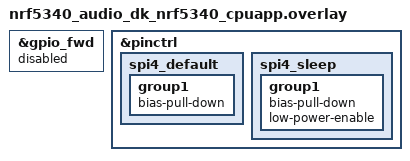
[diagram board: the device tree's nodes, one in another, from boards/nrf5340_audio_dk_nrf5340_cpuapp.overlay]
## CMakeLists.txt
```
#
# Copyright (c) 2026 Nordic Semiconductor ASA
#
# SPDX-License-Identifier: LicenseRef-Nordic-5-Clause
#

cmake_minimum_required(VERSION 3.20.0)

# Register zego bricks: button, led, wifi, network, wifi_ble_prov.
# Paths are relative to this CMakeLists.txt which lives inside zego/, so
# sibling bricks are under ../bricks/<name>/.
get_filename_component(ZEGO_BUTTON_DIR       ${CMAKE_CURRENT_SOURCE_DIR}/../bricks/button       REALPATH)
get_filename_component(ZEGO_LED_DIR          ${CMAKE_CURRENT_SOURCE_DIR}/../bricks/led          REALPATH)
get_filename_component(ZEGO_WIFI_DIR         ${CMAKE_CURRENT_SOURCE_DIR}/../bricks/wifi         REALPATH)
get_filename_component(ZEGO_NETWORK_DIR      ${CMAKE_CURRENT_SOURCE_DIR}/../bricks/network      REALPATH)
get_filename_component(ZEGO_WIFI_BLE_PROV_DIR ${CMAKE_CURRENT_SOURCE_DIR}/../bricks/wifi_ble_prov REALPATH)
get_filename_component(ZEGO_MEMONITOR_DIR    ${CMAKE_CURRENT_SOURCE_DIR}/../bricks/memonitor    REALPATH)
get_filename_component(ZEGO_UX_DIR            ${CMAKE_CURRENT_SOURCE_DIR}/../bricks/ux           REALPATH)
get_filename_component(ZEGO_NTP_DIR           ${CMAKE_CURRENT_SOURCE_DIR}/../bricks/ntp          REALPATH)
list(APPEND EXTRA_ZEPHYR_MODULES
  ${ZEGO_BUTTON_DIR}
  ${ZEGO_LED_DIR}
  ${ZEGO_WIFI_DIR}
  ${ZEGO_NETWORK_DIR}
  ${ZEGO_WIFI_BLE_PROV_DIR}
  ${ZEGO_MEMONITOR_DIR}
  ${ZEGO_UX_DIR}
  ${ZEGO_NTP_DIR}
)

find_package(Zephyr REQUIRED HINTS $ENV{ZEPHYR_BASE})
project(nordic_wifi_app_template)

target_include_directories(app PUBLIC ${ZEPHYR_BASE}/subsys/net/ip)

# All bricks are provided via EXTRA_ZEPHYR_MODULES above (zego/wifi,
# zego/network, zego/button, zego/led, zego/wifi_ble_prov, zego/ux).
# Add application modules below as the project grows.

# APP_VERSION_STRING, PRD_VERSION, SPECS_VERSION are injected by
# zego/wifi/CMakeLists.txt via target_compile_definitions.
target_sources(app PRIVATE
  src/main.c
  src/modules/network/net_event_mgmt_app.c
)
```

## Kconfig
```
#
# Copyright (c) 2026 Nordic Semiconductor ASA
#
# SPDX-License-Identifier: LicenseRef-Nordic-5-Clause
#

menu "Nordic Wi-Fi App Template"

config APP_WIFI_SSID
	string "Wi-Fi SoftAP SSID"
	default "nRF7x_AP"
	help
	  SSID used when operating in SoftAP or P2P_GO mode.

config APP_WIFI_PASSWORD
	string "Wi-Fi SoftAP Password"
	default "12345678"
	help
	  Password for SoftAP (min 8 characters for WPA2).

# mode_selector and network Kconfig provided by zego/wifi and zego/network
# (EXTRA_ZEPHYR_MODULES) — no rsource needed here.
# button, led, and ux Kconfig registered via EXTRA_ZEPHYR_MODULES
# (zego/button, zego/led, zego/ux).

endmenu

source "Kconfig.zephyr"
```

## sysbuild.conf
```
#
# Copyright (c) 2026 Nordic Semiconductor ASA
#
# SPDX-License-Identifier: LicenseRef-Nordic-5-Clause
#

# Wi-Fi support
SB_CONFIG_WIFI_NRF70=y
# Partition Manager deprecated after NCS v3.3.0
SB_CONFIG_PARTITION_MANAGER=n
SB_CONFIG_MERGED_HEX_FILES=y

# nRF5340 (nrf7002dk) only: BLE controller runs on the network core over IPC.
# Build the upstream Zephyr hci_ipc sample as the netcore image so
# CONFIG_ZEGO_WIFI_BLE_PROV can open the HCI driver.
# On nrf54lm20dk SUPPORT_NETCORE=n (single-core SoC), so this has no effect.
SB_CONFIG_NETCORE_HCI_IPC=y
```

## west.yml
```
manifest:
  version: "0.13"

  defaults:
    remote: ncs

  remotes:
    - name: ncs
      url-base: https://github.com/nrfconnect

  projects:
    # NCS imports zephyr, bootloader, modules, nrfxlib, tools, etc.
    - name: sdk-nrf
      path: nrf
      revision: v3.3.0
      import: true
      remote: ncs
```

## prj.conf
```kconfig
#
# Copyright (c) 2026 Nordic Semiconductor ASA
#
# SPDX-License-Identifier: LicenseRef-Nordic-5-Clause
#

# =========================================================================
# Configuration coverage priority:
# Command line > Overlay files > project boards/<board>.conf > prj.conf > Board defconfig
# (highest)                                                              (lowest)
# =========================================================================

# =========================================================================
# This file contains only:
#   - System-level configuration that belongs to no single module
#   - Module enable/disable flags
#   - Log-level choices (cannot be set via Kconfig.defaults)
#   - Project-specific overrides that differ from module defaults
#   - Shared cross-module settings (TLS, mbedTLS)
#   - Hardware-specific memory and stack tuning
# Module-specific defaults live in each module's Kconfig.defaults file.
# =========================================================================

# =========================================================================
# prj.conf should contain the following sections, if needed, in this order,
# with the given headings. Config values that already match the Kconfig
# default (or are already selected transitively) should be commented out.
# Top-level section headings use "=" bars; sub-sections within a section
# use "-" bars:
# =========================================================================
# Document versions — keep in sync with docs/pm-prd/PRD.md and docs/dev-specs/overview.md Changelog timestamps
# General System Configuration - General system configuration
# ZEGO Module: button/led/wifi/network - configurations for different Zego modules
# APP  Module: app/ntp/app_http/app_mqtt - configurations for different APP modules
# Thread Stack Configuration - Thread stack configuration
# Heap Configuration - Heap configuration   
# mbedTLS - mbedTLS configuration
# Shell - shell configuration
# Logging Configuration
# Optimization - Optimization configuration
# =========================================================================
# Reminder: this header block (down to this line) should be copied verbatim
# into any new prj.conf-style config file (e.g. new boards/*.conf files) so
# the same section order and bar conventions are followed consistently.
# =========================================================================

# =========================================================================
# Document versions — keep in sync with docs/pm-prd/PRD.md and
# docs/dev-specs/overview.md Changelog timestamps.
# =========================================================================
CONFIG_ZEGO_APP_PRD_VERSION="2026-07-01-10-50"
CONFIG_ZEGO_APP_SPECS_VERSION="2026-07-01-10-54"

# =========================================================================
# General System Configuration - General system configuration
# =========================================================================

# -------------------------------------------------------------------------
# System
# -------------------------------------------------------------------------
# CONFIG_REBOOT already unconditionally selected by ZEGO_WIFI_MODE_SELECTOR
# (zego/wifi's Kconfig, auto-enabled here via NRF70_AP_MODE) — verified via
# build (.config unchanged).
# CONFIG_REBOOT=y

# -------------------------------------------------------------------------
# Debugging
# -------------------------------------------------------------------------
# CONFIG_STACK_SENTINEL=y
CONFIG_DEBUG_COREDUMP=y
CONFIG_DEBUG_COREDUMP_BACKEND_LOGGING=y
CONFIG_DEBUG_COREDUMP_MEMORY_DUMP_MIN=y
CONFIG_SHELL_CMDS_RESIZE=n

# -------------------------------------------------------------------------
# Kernel options
# -------------------------------------------------------------------------
CONFIG_ENTROPY_GENERATOR=y
# CONFIG_INIT_STACKS already selected below by CONFIG_ZEGO_MEMONITOR_ZVIEW —
# verified via build (.config unchanged).
# CONFIG_INIT_STACKS=y

# -------------------------------------------------------------------------
# Eventfd — WPA supplicant needs more than 2
# -------------------------------------------------------------------------
CONFIG_EVENTFD=y
CONFIG_ZVFS_OPEN_MAX=48
CONFIG_ZVFS_EVENTFD_MAX=16
CONFIG_POSIX_API=y

# -------------------------------------------------------------------------
# SMF + Zbus
# -------------------------------------------------------------------------
# SMF and ZBUS already selected by zego/button and zego/led ("select SMF" /
# "select ZBUS" in their Kconfig) — verified via build (.config unchanged).
# CONFIG_SMF=y
CONFIG_SMF_INITIAL_TRANSITION=y
CONFIG_SMF_ANCESTOR_SUPPORT=y
# CONFIG_ZBUS=y
CONFIG_ZBUS_PRIORITY_BOOST=y
CONFIG_ZBUS_RUNTIME_OBSERVERS=y
CONFIG_ZBUS_MSG_SUBSCRIBER=y

# -------------------------------------------------------------------------
# GPIO / DK Library
# -------------------------------------------------------------------------
# GPIO and DK_LIBRARY already selected via ZEGO_BUTTON_BACKEND_DK /
# ZEGO_LED_BACKEND_DK (the default backend, confirmed in every boards/*.conf)
# -> DK_LIBRARY "select GPIO" — verified via build (.config unchanged).
# CONFIG_GPIO=y
# CONFIG_DK_LIBRARY=y

# -------------------------------------------------------------------------
# JSON
# -------------------------------------------------------------------------
CONFIG_JSON_LIBRARY=y

# -------------------------------------------------------------------------
# Persistent storage — NVS / Settings / Flash
# -------------------------------------------------------------------------
# Used by the Wi-Fi mode selector (persists the active STA/SoftAP/P2P_GO
# mode across reboots) and by the Wi-Fi credentials backend
# (CONFIG_WIFI_CREDENTIALS_BACKEND_SETTINGS, persists STA credentials).
# SETTINGS / FLASH / FLASH_MAP / FLASH_PAGE_LAYOUT already unconditionally
# selected by ZEGO_WIFI_MODE_SELECTOR (zego/wifi's Kconfig, auto-enabled here
# via NRF70_AP_MODE) — verified via build (.config unchanged).
# CONFIG_SETTINGS=y
CONFIG_SETTINGS_NVS=y
CONFIG_NVS=y
# CONFIG_FLASH=y
# CONFIG_FLASH_MAP=y
# CONFIG_FLASH_PAGE_LAYOUT=y

# =========================================================================
# ZEGO Module: button/led/wifi/network - configurations for different Zego modules
# =========================================================================

# -------------------------------------------------------------------------
# Zego module configuration
# -------------------------------------------------------------------------
CONFIG_ZEGO_BUTTON=y
CONFIG_ZEGO_LED=y

CONFIG_ZEGO_WIFI=y
# Default mode: STA — change to SOFTAP or P2P_GO via the mode-selector shell
CONFIG_ZEGO_WIFI_DEFAULT_MODE_STA=y
# Enable all four Wi-Fi modes on all boards.
CONFIG_ZEGO_WIFI_MODE_SOFTAP_ENABLED=y
CONFIG_ZEGO_WIFI_LOG_LEVEL_INF=y

CONFIG_ZEGO_WIIF_SOFTAP_SSID="nRF7x_AP"
CONFIG_ZEGO_WIIF_SOFTAP_PASSWORD="12345678"

# BLE Wi-Fi provisioning (zego/wifi_ble_prov module)
# Disabled per-board when flash budget is too tight (see boards/*.conf).
# Log levels only set in boards conf where the module is actually enabled,
# to avoid Kconfig "choice symbol selected but no selection" warnings.
# CONFIG_ZEGO_WIFI_BLE_PROV=y

# P2P_GC has no target-GO-MAC build option: the GO is paired at runtime via a
# Button 0 double-click (WPS PIN) and the learned MAC is stored in NVS.

# -------------------------------------------------------------------------
# Wi-Fi Configuration (STA + SoftAP + P2P)
# -------------------------------------------------------------------------
# WIFI / WIFI_NRF70 / WIFI_NM_WPA_SUPPLICANT: now unconditionally selected by
# ZEGO_NETWORK (zego/network's Kconfig) now that the ZEGO_NETWORK/ZEGO_WIFI/
# NETWORKING Kconfig cycle is fixed — verified via build (.config unchanged).
# CONFIG_WIFI=y
# CONFIG_WIFI_NRF70=y

# WPA supplicant — supports STA and SoftAP; add wifi-p2p snippet for P2P + WPS
# CONFIG_WIFI_NM_WPA_SUPPLICANT=y
CONFIG_WIFI_NM_WPA_SUPPLICANT_AP=y

# WEP and WPA1/TKIP (LEGACY_CRYPTO) are both cryptographically broken (WEP:
# full key recovery in minutes via aircrack-ng-class attacks; TKIP: Beck-Tews/
# Ohigashi-Morii partial plaintext recovery) and have been out of Wi-Fi
# Alliance certification since 2004 / 2012 respectively. WPA2-AES/CCMP has
# been mandatory in every certified AP since 2006, so a router with no WPA2
# fallback is effectively extinct — the compatibility cost of dropping both
# is negligible, and doing so removes an RC4/MD5 downgrade attack surface
# from this device's Wi-Fi stack entirely. This app only uses personal
# WPA2/WPA3-PSK (no enterprise/EAP), which doesn't touch either symbol.
CONFIG_WIFI_NM_WPA_SUPPLICANT_WEP=n
CONFIG_WIFI_NM_WPA_SUPPLICANT_LEGACY_CRYPTO=n

# nRF70 SoftAP mode
CONFIG_NRF70_AP_MODE=y
CONFIG_NRF_WIFI_LOW_POWER=n
# Limit SoftAP to 3 simultaneous clients (Zephyr default is 4)
CONFIG_WIFI_MGMT_AP_MAX_NUM_STA=3

# nRF70 P2P mode (Wi-Fi Direct) — not enabled here; add the wifi-p2p snippet
# (-Dnordic-wifi-app-template_SNIPPET=wifi-p2p) to enable it. The snippet sets
# CONFIG_NRF70_P2P_MODE=y, which in turn enables P2P_GO and P2P_GC as
# selectable Wi-Fi modes by default (ZEGO_WIFI_MODE_P2P_GO_ENABLED /
# _GC_ENABLED both default y when NRF70_P2P_MODE=y — see zego/bricks/wifi/Kconfig).

# -------------------------------------------------------------------------
# Networking
# -------------------------------------------------------------------------
# CONFIG_NETWORKING already unconditionally selected by ZEGO_WIFI (zego/wifi's
# Kconfig) — verified via build (.config unchanged).
# CONFIG_NETWORKING=y
# CONFIG_NET_SOCKETS / NET_IPV4 / NET_UDP / NET_TCP / NET_DHCPV4 already
# unconditionally selected by ZEGO_NETWORK (zego/network's Kconfig) —
# verified via build (.config unchanged).
# CONFIG_NET_SOCKETS=y
# CONFIG_NET_IPV4=y
# CONFIG_NET_UDP=y
# CONFIG_NET_TCP=y
CONFIG_NET_IPV6=n

# DHCP Server (SoftAP / P2P_GO)
# CONFIG_NET_DHCPV4=y
CONFIG_NET_DHCPV4_SERVER=y
CONFIG_NET_DHCPV4_SERVER_ADDR_COUNT=3
# Static IP for SoftAP / P2P_GO
CONFIG_NET_CONFIG_SETTINGS=y
CONFIG_NET_CONFIG_MY_IPV4_ADDR="192.168.7.1"
CONFIG_NET_CONFIG_MY_IPV4_NETMASK="255.255.255.0"
CONFIG_NET_CONFIG_MY_IPV4_GW="192.168.7.1"
CONFIG_NET_CONFIG_INIT_TIMEOUT=0

# -------------------------------------------------------------------------
# STA mode — Connection Manager + Wi-Fi Credentials
# -------------------------------------------------------------------------
# CONFIG_NET_CONNECTION_MANAGER / L2_WIFI_CONNECTIVITY / WIFI_CREDENTIALS /
# DNS_RESOLVER already unconditionally selected by ZEGO_NETWORK (zego/network's
# Kconfig) — verified via build (.config unchanged).
# CONFIG_NET_CONNECTION_MANAGER=y
# CONFIG_L2_WIFI_CONNECTIVITY=y
CONFIG_L2_WIFI_CONNECTIVITY_AUTO_CONNECT=n
CONFIG_L2_WIFI_CONNECTIVITY_AUTO_DOWN=n

# Persistent credential store — enables 'wifi cred' shell commands
# CONFIG_WIFI_CREDENTIALS=y
CONFIG_WIFI_CREDENTIALS_BACKEND_SETTINGS=y
# CONFIG_DNS_RESOLVER=y
CONFIG_DNS_RESOLVER_AUTO_INIT=y

# -------------------------------------------------------------------------
# Network buffers — tuned for reliable operation
# -------------------------------------------------------------------------
# Using default VAR pool (NET_BUF_POOL_VAR_DEFINE / k_heap).
# Each buffer is sized to the actual payload, so small packets (DNS, ACKs)
# don't waste a full MTU slot. The pool heap is a dedicated static arena
# (not drawn from _system_heap) visible to ZView as net_buf_mem_pool_rx/tx_bufs.
CONFIG_NET_PKT_RX_COUNT=16
CONFIG_NET_PKT_TX_COUNT=24
CONFIG_NET_BUF_RX_COUNT=16
CONFIG_NET_BUF_TX_COUNT=32
CONFIG_NRF70_RX_NUM_BUFS=16
CONFIG_NET_TC_TX_COUNT=1
CONFIG_NET_IF_UNICAST_IPV4_ADDR_COUNT=1
CONFIG_NET_MAX_CONTEXTS=16
CONFIG_NET_MAX_CONN=16
CONFIG_NET_CONTEXT_SYNC_RECV=y
CONFIG_NET_CONTEXT_RCVTIMEO=y
CONFIG_NET_L2_ETHERNET=y
CONFIG_NET_SOCKETS_POLL_MAX=10

# -------------------------------------------------------------------------
# P2P debug — enable wpa_supplicant MSG_DEBUG to see join_scan_count,
# "Failed to find BSS/GO", "Join scan attempt N", P2P state transitions.
# Very verbose: filter with 'grep P2P' in the terminal.
# Remove when debugging is done.
# -------------------------------------------------------------------------
#CONFIG_WIFI_NM_WPA_SUPPLICANT_LOG_LEVEL_DBG=y

CONFIG_ZEGO_NETWORK=y
CONFIG_ZEGO_NETWORK_LOG_LEVEL_INF=y

# -------------------------------------------------------------------------
# mDNS — device reachable as nrf7x.local on any active Wi-Fi interface
# -------------------------------------------------------------------------
#CONFIG_ZEGO_NETWORK_MDNS=y
#CONFIG_NET_HOSTNAME="nrf7x"
# Uncomment to also register _http._tcp.local DNS-SD service:
#CONFIG_ZEGO_NETWORK_MDNS_HTTP_PORT=80

# =========================================================================
# APP  Module: app/ntp/app_http/app_mqtt - configurations for different APP modules
# =========================================================================

# -------------------------------------------------------------------------
# UX module — Button 0 gestures + LED 0 Wi-Fi state feedback
# -------------------------------------------------------------------------
CONFIG_ZEGO_UX=y

# -------------------------------------------------------------------------
# memonitor — periodic heap + thread sampler, /api/heaps, /api/threads (FR-107/108)
# Set =n to disable: the Thread Monitor and Heap Monitor sections will be
# hidden automatically on the webpage.
# -------------------------------------------------------------------------
CONFIG_ZEGO_MEMONITOR=y
CONFIG_ZEGO_MEMONITOR_INTERVAL_MS=5000
# ZEGO_MEMONITOR_ZVIEW selects all required Kconfig symbols:
#   INIT_STACKS, THREAD_MONITOR, THREAD_STACK_INFO, THREAD_NAME,
#   THREAD_RUNTIME_STATS, SYS_HEAP_RUNTIME_STATS.
# CONFIG_STACK_SENTINEL=n is mandatory: it overwrites the 0xaa init-fill with
# 0xf0f0f0f0, causing ZView to report 100% stack usage on every thread.
CONFIG_ZEGO_MEMONITOR_ZVIEW=y
CONFIG_STACK_SENTINEL=n

# -------------------------------------------------------------------------
# ntp — SNTP time synchronization (zego/bricks/ntp)
# Uses pool.ntp.org by default (see zego/bricks/ntp/Kconfig for all options).
# -------------------------------------------------------------------------
CONFIG_ZEGO_NTP=y
CONFIG_ZEGO_NTP_LOG_LEVEL_INF=y
# Real-world timestamps in log output (requires ZEGO_NTP to set CLOCK_REALTIME)
CONFIG_LOG_TIMESTAMP_USE_REALTIME=y

# =========================================================================
# Thread Stack Configuration - Thread stack configuration
# =========================================================================
# All values measured on nRF54LM20DK + nRF7002EB2 using CONFIG_THREAD_ANALYZER.
# Sizing rule: max_hwm / 0.9 (10 % headroom). Adjust for your application load.
# Watermark Bytes 1496/0.9=1662 (WiFi reconnect + active uploads)
CONFIG_MAIN_STACK_SIZE=4096
# Watermark Bytes 4952/0.9=5502 (wpa_cli_cmd + _wpa_ctrl_command + zvfs_poll_internal)
CONFIG_SYSTEM_WORKQUEUE_STACK_SIZE=5502
# Watermark Bytes 4432/0.9=4924
CONFIG_NET_CONNECTION_MANAGER_MONITOR_STACK_SIZE=4924
# Watermark Bytes 1168/0.9=1297; kept at 2048 for network burst headroom
CONFIG_NET_RX_STACK_SIZE=2048
# Watermark Bytes 792/0.9=880; kept at 2048 for network burst headroom
CONFIG_NET_TX_STACK_SIZE=2048
# Watermark Bytes 2940/0.9=3266
CONFIG_NET_MGMT_EVENT_STACK_SIZE=3266
# Watermark Bytes 5392/0.9=5991 (measured on nRF54LM20DK + nRF7002EB2)
CONFIG_WIFI_NM_WPA_SUPPLICANT_THREAD_STACK_SIZE=8192
# Watermark Bytes 3896/0.9=4328
CONFIG_WIFI_NM_WPA_SUPPLICANT_WQ_STACK_SIZE=4328
# Watermark Bytes 1088/0.9=1208
CONFIG_NRF70_BH_WQ_STACK_SIZE=1208
# Watermark Bytes 792/0.9=880
CONFIG_NRF70_IRQ_WQ_STACK_SIZE=880
# Watermark Bytes 248/0.9=276
CONFIG_L2_WIFI_CONN_WQ_STACK_SIZE=2760

CONFIG_SHELL_STACK_SIZE=8192

# =========================================================================
# Heap Configuration - Heap configuration
# =========================================================================
# CONFIG_HEAP_MEM_POOL_SIZE is the user floor. Kconfig enforces a minimum equal
# to the sum of all HEAP_MEM_POOL_ADD_SIZE_* values (~184 KB for Wi-Fi + BLE):
#   ADD_SIZE_NRF70=150000  ADD_SIZE_HOSTAP=30000  ADD_SIZE_BOARD=4096  ADD_SIZE_POSIX=256
# Setting a value below that sum is silently raised to the sum unless
# HEAP_MEM_POOL_IGNORE_MIN=y is set.
# Runtime measurements: _system_heap peaked at 57928 B (89 %) of the previous
# 64780 B ceiling in STA/SoftAP mode. P2P_GO adds ~6-8 KB more for struct
# p2p_data, the P2P GO's wpa_auth context, and the PMKSA cache (528 B).
# Without enough headroom, pmksa_cache_auth_init() returns NULL, causing
# "PMKSA cache initialization failed" + "WPA initialization failed" and a
# 15 s WPS_CHECK_PIN ctrl-iface timeout.
# New ceiling: 131072 B (20 % headroom above estimated P2P_GO peak of ~104 KB).
# With NRF_WIFI_GLOBAL_HEAP=n and WIFI_NM_WPA_SUPPLICANT_GLOBAL_HEAP=n the
# HEAP_MEM_POOL_ADD_SIZE_* contributions from WiFi + WPA supplicant are removed.
# Only app-level allocations remain in _system_heap — re-measure after split.
CONFIG_HEAP_MEM_POOL_SIZE=4096
CONFIG_HEAP_MEM_POOL_IGNORE_MIN=y
# WiFi driver moved to dedicated K_HEAPs — visible as wifi_drv_ctrl_mem_pool and
# wifi_drv_data_mem_pool in ZView.
# Re-measure ZView watermarks after a full STA/P2P connect + TLS cycle, then set
# each to watermark / 0.8.
CONFIG_NRF_WIFI_GLOBAL_HEAP=n
CONFIG_NRF_WIFI_CTRL_HEAP_SIZE=16384
CONFIG_NRF_WIFI_DATA_HEAP_SIZE=40960
# WPA supplicant moved to dedicated K_HEAP — visible as wifi_nm_wpa_supplicant_mem_pool in ZView.
# Re-measure ZView watermark after a full connect cycle, then set to peak / 0.8.
# Use the shared Zephyr system heap for wpa_supplicant (the NCS default, =y).
# A dedicated supplicant K_HEAP (=n) was previously used for per-pool ZView
# monitoring, but it starved the P2P_GO hostapd WPS Registrar: wps_registrar_init()
# failed ("Failed to initialize WPS Registrar") and the GO AP interface never
# reached AP-ENABLED, so P2P pairing was impossible. The nRF P2P sample uses the
# global heap and works; matching it fixes the GO. Confirmed on hardware.
# (Trade-off: the supplicant heap no longer appears as a separate ZView pool;
# track it via the system-heap watermark instead.)
CONFIG_WIFI_NM_WPA_SUPPLICANT_GLOBAL_HEAP=y

# =========================================================================
# mbedTLS - mbedTLS configuration
# =========================================================================
CONFIG_MBEDTLS_ENABLE_HEAP=y
# Watermark Bytes 69504/0.8=86880 (measured with global heap; re-measure with dedicated heap)
CONFIG_MBEDTLS_HEAP_SIZE=86880
# NCS v3.4.0 updated Mbed TLS to v4.1.0, which removed the legacy mbedcrypto
# APIs and the "legacy crypto config path" this app previously routed through.
# CONFIG_NRF_SECURITY is now a computed symbol (auto-enabled for Nordic SoCs)
# and CONFIG_MBEDTLS_LEGACY_CRYPTO_C no longer exists, so neither is set here.
# Unlike a first assessment suggested, this is NOT a no-op change: nrf_security's
# PSA-only config generation did not forward MBEDTLS_MEMORY_DEBUG into the
# generated psa/crypto_config.h, so mbedtls_memory_buffer_alloc_cur_get()/
# _max_get() were unavailable and the mbedtls_heap row was omitted from ZView.
# Fixed by a vendored patch carried in zego/patches/nrf_security/ (reapply
# after west update) - see bricks/memonitor/Kconfig for the resulting
# CONFIG_MBEDTLS_MEMORY_DEBUG auto-select logic.

# =========================================================================
# Shell - shell configuration
# =========================================================================
# Shell — required for mode selector UX and wifi connect / wifi cred commands
CONFIG_SHELL=y
CONFIG_NET_L2_WIFI_SHELL=y
CONFIG_WIFI_SHELL_MAX_AP_STA=3

# =========================================================================
# Logging Configuration
# =========================================================================
CONFIG_LOG=y
CONFIG_LOG_BUFFER_SIZE=4096
# Deferred mode: log messages are queued and processed in the logging thread,
# not inline in the calling thread (net_mgmt event thread, etc.)
CONFIG_LOG_MODE_DEFERRED=y
# NET_LOG=y is required for any NET_*_LOG_LEVEL_* choice to become visible
# (all net module log choices depend on NET_LOG).
# All modules explicitly silenced to avoid FLASH overflow; only NET_SOCKETS at DBG.
CONFIG_NET_LOG=n
# CONFIG_NET_SOCKETS_LOG_LEVEL_INF=y
# # CONFIG_MQTT_LOG_LEVEL_DBG=y
# # CONFIG_MQTT_HELPER_LOG_LEVEL_DBG=y
# CONFIG_SOCKS_LOG_LEVEL_OFF=y
# CONFIG_TLS_CREDENTIALS_LOG_LEVEL_OFF=y
# CONFIG_DNS_RESOLVER_LOG_LEVEL_OFF=y
# CONFIG_DNS_SD_LOG_LEVEL_OFF=y
# CONFIG_DNS_SOCKET_DISPATCHER_LOG_LEVEL_OFF=y
# CONFIG_LATMON_LOG_LEVEL_OFF=y
# CONFIG_LLMNR_RESPONDER_LOG_LEVEL_OFF=y
# CONFIG_LWM2M_LOG_LEVEL_OFF=y
# CONFIG_MDNS_RESPONDER_LOG_LEVEL_OFF=y
# CONFIG_NET_6LO_LOG_LEVEL_OFF=y
# CONFIG_NET_ARP_LOG_LEVEL_OFF=y
# CONFIG_NET_CAPTURE_LOG_LEVEL_OFF=y
# CONFIG_NET_CONFIG_LOG_LEVEL_OFF=y
# CONFIG_NET_CONN_LOG_LEVEL_OFF=y
# CONFIG_NET_CONNECTION_MANAGER_LOG_LEVEL_OFF=y
# CONFIG_NET_CONTEXT_LOG_LEVEL_OFF=y
# CONFIG_NET_CORE_LOG_LEVEL_OFF=y
# CONFIG_NET_DHCPV4_LOG_LEVEL_OFF=y
# CONFIG_NET_DHCPV4_SERVER_LOG_LEVEL_OFF=y
# CONFIG_NET_DHCPV6_LOG_LEVEL_OFF=y
# CONFIG_NET_DSA_LOG_LEVEL_OFF=y
# CONFIG_NET_ETHERNET_BRIDGE_LOG_LEVEL_OFF=y
# CONFIG_NET_GPTP_LOG_LEVEL_OFF=y
# CONFIG_NET_HTTP_SERVER_LOG_LEVEL_OFF=y
# CONFIG_NET_ICMPV4_LOG_LEVEL_OFF=y
# CONFIG_NET_ICMPV6_LOG_LEVEL_OFF=y
# CONFIG_NET_IF_LOG_LEVEL_OFF=y
# CONFIG_NET_IPV4_LOG_LEVEL_OFF=y
# CONFIG_NET_IPV4_ACD_LOG_LEVEL_OFF=y
# CONFIG_NET_IPV4_AUTO_LOG_LEVEL_OFF=y
# CONFIG_NET_IPV6_LOG_LEVEL_OFF=y
# CONFIG_NET_IPV6_NBR_CACHE_LOG_LEVEL_OFF=y
# CONFIG_NET_IPV6_ND_LOG_LEVEL_OFF=y
# CONFIG_NET_IPV6_PE_LOG_LEVEL_OFF=y
# CONFIG_NET_L2_ETHERNET_LOG_LEVEL_OFF=y
# CONFIG_NET_L2_IEEE802154_LOG_LEVEL_OFF=y
# CONFIG_NET_L2_IPIP_LOG_LEVEL_OFF=y
# CONFIG_NET_L2_PPP_LOG_LEVEL_OFF=y
# CONFIG_NET_L2_VIRTUAL_LOG_LEVEL_OFF=y
# CONFIG_NET_L2_WIFI_MGMT_LOG_LEVEL_OFF=y
# CONFIG_NET_LLDP_LOG_LEVEL_OFF=y
# CONFIG_NET_MGMT_EVENT_LOG_LEVEL_OFF=y
# CONFIG_NET_OFFLOAD_LOG_LEVEL_OFF=y
# CONFIG_NET_PKT_FILTER_LOG_LEVEL_OFF=y
# CONFIG_NET_PMTU_LOG_LEVEL_OFF=y
# CONFIG_NET_PROMISC_LOG_LEVEL_OFF=y
# CONFIG_NET_PSEUDO_IFACE_LOG_LEVEL_OFF=y
# CONFIG_NET_ROUTE_LOG_LEVEL_OFF=y
# CONFIG_NET_STATISTICS_LOG_LEVEL_OFF=y
# CONFIG_NET_TC_LOG_LEVEL_OFF=y
# CONFIG_NET_TCP_LOG_LEVEL_OFF=y
# CONFIG_NET_TRICKLE_LOG_LEVEL_OFF=y
# CONFIG_NET_UDP_LOG_LEVEL_OFF=y
# CONFIG_NET_UTILS_LOG_LEVEL_OFF=y
# CONFIG_NET_WEBSOCKET_LOG_LEVEL_OFF=y
# CONFIG_NET_ZPERF_LOG_LEVEL_OFF=y
# CONFIG_OPENTHREAD_L2_LOG_LEVEL_OFF=y
# CONFIG_PROMETHEUS_LOG_LEVEL_OFF=y
# CONFIG_PTP_LOG_LEVEL_OFF=y
# CONFIG_SNTP_LOG_LEVEL_OFF=y
# CONFIG_WIFI_CREDENTIALS_LOG_LEVEL_OFF=y
# CONFIG_WIFI_NM_LOG_LEVEL_OFF=y

# =========================================================================
# Optimization
# =========================================================================
# C Library
CONFIG_PICOLIBC=y
CONFIG_MINIMAL_LIBC=n
CONFIG_NEWLIB_LIBC=n
# Compiler optimizations will be set to -Os 
CONFIG_SIZE_OPTIMIZATIONS=y
# Link Time Optimization
# CONFIG_LTO=y
# CONFIG_ISR_TABLES_LOCAL_DECLARATION=y
```

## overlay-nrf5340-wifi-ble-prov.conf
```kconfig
# Shared optional profile for nRF5340-based boards (nRF7002DK and nRF5340 Audio DK):
# enable BLE provisioning while keeping P2P disabled.
# Intended for tighter flash budgets where the wifi-p2p snippet is not used.
CONFIG_ZEGO_WIFI_BLE_PROV=y

# BT RX WQ needs extra stack for wifi_prov indication/notification callbacks
# Watermark Bytes 20072/0.9=22302
CONFIG_BT_RX_STACK_SIZE=22302
# Watermark Bytes 1784/0.9=1982
CONFIG_BT_LONG_WQ_STACK_SIZE=1982
```

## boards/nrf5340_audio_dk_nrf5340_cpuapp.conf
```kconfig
#
# Copyright (c) 2026 Nordic Semiconductor ASA
#
# SPDX-License-Identifier: LicenseRef-Nordic-5-Clause
#

# =========================================================================
# Configuration coverage priority:
# Command line > Overlay files > project boards/<board>.conf > prj.conf > Board defconfig
# (highest)                                                              (lowest)
# =========================================================================

# =========================================================================
# This file contains only:
#   - System-level configuration that belongs to no single module
#   - Module enable/disable flags
#   - Log-level choices (cannot be set via Kconfig.defaults)
#   - Project-specific overrides that differ from module defaults
#   - Shared cross-module settings (TLS, mbedTLS)
#   - Hardware-specific memory and stack tuning
# Module-specific defaults live in each module's Kconfig.defaults file.
# =========================================================================

# =========================================================================
# prj.conf should contain the following sections, if needed, in this order,
# with the given headings. Config values that already match the Kconfig
# default (or are already selected transitively) should be commented out.
# Top-level section headings use "=" bars; sub-sections within a section
# use "-" bars:
# =========================================================================
# Document versions — keep in sync with docs/pm-prd/PRD.md and docs/dev-specs/overview.md Changelog timestamps
# General System Configuration - General system configuration
# ZEGO Module: button/led/wifi/network - configurations for different Zego modules
# APP  Module: app/ntp/app_http/app_mqtt - configurations for different APP modules
# Thread Stack Configuration - Thread stack configuration
# Heap Configuration - Heap configuration   
# mbedTLS - mbedTLS configuration
# Shell - shell configuration
# Logging Configuration
# Optimization - Optimization configuration
# =========================================================================
# Reminder: this header block (down to this line) should be copied verbatim
# into any new prj.conf-style config file (e.g. new boards/*.conf files) so
# the same section order and bar conventions are followed consistently.
# =========================================================================


# ============================================================================
#   nRF5340 Audio DK + nRF7002EK: 5 user buttons (BUTTON0/1/2/3/4), 9 LEDs
# ============================================================================
# nRF5340 Audio DK + nRF7002EK
#   5 user buttons (DK bitmask order):
#     0 → VOL-       (KEY_VOLUMEDOWN)
#     1 → VOL+       (KEY_VOLUMEUP)
#     2 → PLAY/PAUSE (KEY_3)
#     3 → BTN4       (KEY_4)
#     4 → BTN5       (KEY_5)
#   9 LEDs:
#     0-2 → RGB1  (led_0/1/2, PWM-capable)
#     3-5 → RGB2  (led_3/4/5)
#     6   → mono blue  (led_6)
#     7-8 → mono green (led_7/8)
#   UX ROTATE uses RGB2 only (indices 3-5) via CONFIG_ZEGO_UX_ROTATE_FIRST_LED/COUNT
#
CONFIG_ZEGO_BUTTON_NUM_BUTTONS=5
# CONFIG_ZEGO_BUTTON_BACKEND_DK already the brick's default choice.
# CONFIG_ZEGO_BUTTON_BACKEND_DK=y
CONFIG_ZEGO_LED_NUM_LEDS=9
# CONFIG_ZEGO_LED_BACKEND_DK already the brick's default choice.
# CONFIG_ZEGO_LED_BACKEND_DK=y

# UX module: rotate RGB2 (LEDs 3, 4, 5) during connecting; solid green (LED 4) when connected;
# blue (LED 5) breathes during BLE provisioning / P2P pairing.
CONFIG_ZEGO_UX_ROTATE_FIRST_LED=3
CONFIG_ZEGO_UX_ROTATE_COUNT=3
CONFIG_ZEGO_UX_CONNECTED_LED=4
CONFIG_ZEGO_UX_CONNECTED_LED_GREEN_ONLY=y
CONFIG_ZEGO_UX_PAIRING_LED_IDX=5
CONFIG_ZEGO_UX_ERROR_LED_IDX=3
# UX gesture button: BTN5 (idx 4) instead of VOL- (idx 0), leaving VOL- free for the app.
CONFIG_ZEGO_UX_BUTTON_IDX=4

# Below configurations are same as nrf7002dk_nrf5340_cpuapp.conf, since nRF5340 is the wifi host.

# ============================================================================
# nRF7002DK: BLE provisioning support
# ============================================================================
# BLE provisioning does not fit on nRF7002DK (nRF5340, 1 MB flash) when
# a heavy application is also present.  Enable it only if you have enough
# flash headroom; otherwise leave it disabled here and rely on the
# wifi connect / wifi cred shell options for STA provisioning.
# Remove or override this line to re-enable on nRF7002DK.
CONFIG_ZEGO_WIFI_BLE_PROV=n


# ============================================================================
# Memory / Stack sizes — nRF7002DK measurements
# All values measured on nRF7002DK using CONFIG_THREAD_ANALYZER.
# Sizing rule: max_hwm / 0.9 (10 % headroom). Heap: max_hwm / 0.8 (20 % headroom).
# Override prj.conf values which were measured on nRF54LM20DK + nRF7002EB2.
# ============================================================================
# Watermark Bytes 7880/0.9=8755
CONFIG_WIFI_NM_WPA_SUPPLICANT_THREAD_STACK_SIZE=8755
# Watermark Bytes 3552/0.9=3946
CONFIG_WIFI_NM_WPA_SUPPLICANT_WQ_STACK_SIZE=3946
# Watermark Bytes 4560/0.9=5066
CONFIG_SYSTEM_WORKQUEUE_STACK_SIZE=5066
# Watermark Bytes 1168/0.9=1297
CONFIG_NRF70_BH_WQ_STACK_SIZE=1297
# Watermark Bytes 792/0.9=880
CONFIG_NRF70_IRQ_WQ_STACK_SIZE=880
# Watermark Bytes 88128/0.8=110160
CONFIG_HEAP_MEM_POOL_SIZE=110160

# ============================================================================
# nRF7002DK: Silence the  "MBEDTLS_PSA_CRYPTO_EXTERNAL_RNG_ALLOW_NON_CSPRNG" build warning
# ============================================================================
# Silence the v3.3.0 Kconfig warning:
#   "MBEDTLS_PSA_CRYPTO_EXTERNAL_RNG_ALLOW_NON_CSPRNG was assigned the value
#    'y' but got the value 'n'"
# The nrf7002dk_nrf5340_cpuapp_defconfig sets this symbol to 'y'.
# NRF_SECURITY selects DISABLE_MBEDTLS_BUILTIN and sets
# MBEDTLS_CFG_FILE="nrf-config.h", making the Kconfig.mbedtls menu
# (depends on MBEDTLS_BUILTIN && MBEDTLS_CFG_FILE="config-mbedtls.h")
# invisible.  The dependency is therefore unmet.  Explicitly clearing the
# symbol here overrides the defconfig assignment so the assigned value ('n')
# matches the evaluated value ('n').
#
# A related warning ("The choice symbol MBEDTLS_PSA_CRYPTO_EXTERNAL_RNG was
# selected (set =y) but no symbol ended up as the choice selection") also
# originates from the board defconfig and cannot be silenced at the app
# level: kconfiglib does not honour "# CONFIG_CHOICE_SYMBOL is not set" for
# choice symbols, so the defconfig's choice assignment persists.  This is a
# known upstream issue (NRF_SECURITY overrides the choice via CMake, but the
# Kconfig layer is left inconsistent).  The warning is harmless; nrf_security
# always provides its own RNG implementation regardless of this choice.
# ============================================================================
# CONFIG_MBEDTLS_PSA_CRYPTO_EXTERNAL_RNG_ALLOW_NON_CSPRNG is not set
```

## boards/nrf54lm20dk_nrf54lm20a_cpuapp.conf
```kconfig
#
# Copyright (c) 2026 Nordic Semiconductor ASA
#
# SPDX-License-Identifier: LicenseRef-Nordic-5-Clause
#

# =========================================================================
# Configuration coverage priority:
# Command line > Overlay files > project boards/<board>.conf > prj.conf > Board defconfig
# (highest)                                                              (lowest)
# =========================================================================

# =========================================================================
# This file contains only:
#   - System-level configuration that belongs to no single module
#   - Module enable/disable flags
#   - Log-level choices (cannot be set via Kconfig.defaults)
#   - Project-specific overrides that differ from module defaults
#   - Shared cross-module settings (TLS, mbedTLS)
#   - Hardware-specific memory and stack tuning
# Module-specific defaults live in each module's Kconfig.defaults file.
# =========================================================================

# =========================================================================
# prj.conf should contain the following sections, if needed, in this order,
# with the given headings. Config values that already match the Kconfig
# default (or are already selected transitively) should be commented out.
# Top-level section headings use "=" bars; sub-sections within a section
# use "-" bars:
# =========================================================================
# Document versions — keep in sync with docs/pm-prd/PRD.md and docs/dev-specs/overview.md Changelog timestamps
# General System Configuration - General system configuration
# ZEGO Module: button/led/wifi/network - configurations for different Zego modules
# APP  Module: app/ntp/app_http/app_mqtt - configurations for different APP modules
# Thread Stack Configuration - Thread stack configuration
# Heap Configuration - Heap configuration   
# mbedTLS - mbedTLS configuration
# Shell - shell configuration
# Logging Configuration
# Optimization - Optimization configuration
# =========================================================================
# Reminder: this header block (down to this line) should be copied verbatim
# into any new prj.conf-style config file (e.g. new boards/*.conf files) so
# the same section order and bar conventions are followed consistently.
# =========================================================================

# =========================================================================
# ZEGO Module: button/led/wifi_prov - configurations for different Zego modules
# =========================================================================

# -------------------------------------------------------------------------
# button
# -------------------------------------------------------------------------
CONFIG_ZEGO_BUTTON_NUM_BUTTONS=3
# CONFIG_ZEGO_BUTTON_BACKEND_DK already the brick's default choice.
# CONFIG_ZEGO_BUTTON_BACKEND_DK=y

# -------------------------------------------------------------------------
# led
# -------------------------------------------------------------------------
# CONFIG_ZEGO_LED_NUM_LEDS already defaults to 4 in zego/led's Kconfig.
# CONFIG_ZEGO_LED_NUM_LEDS=4
# CONFIG_ZEGO_LED_BACKEND_DK already the brick's default choice.
# CONFIG_ZEGO_LED_BACKEND_DK=y

# -------------------------------------------------------------------------
# wifi_ble_prov
# -------------------------------------------------------------------------
CONFIG_ZEGO_WIFI_BLE_PROV=y
CONFIG_ZEGO_WIFI_BLE_PROV_LOG_LEVEL_INF=y
CONFIG_BT_WIFI_PROV_LOG_LEVEL_INF=y
# BT RX WQ needs extra stack for wifi_prov indication/notification callbacks
# BT LW WQ: Watermark Bytes 2008/0.8=2510
CONFIG_BT_LONG_WQ_STACK_SIZE=2510
# BT RX WQ: Watermark Bytes 20080/0.9=22311
CONFIG_BT_RX_STACK_SIZE=22311

# =========================================================================
# Shell - shell configuration
# =========================================================================
# NET_SHELL cost: +49.8 KB Flash / +1.4 KB RAM (measured Jun 17 2026)
# Enable only when debugging with net iface / net sockets / net ping / etc.
CONFIG_NET_SHELL=y
# OBJ_CORE cost: +12.7 KB Flash / +11.8 KB RAM (measured Jun 17 2026, on top of NET_SHELL)
# Enables socket Creator/Name/Lifetime columns in 'net sockets'
#CONFIG_OBJ_CORE=y
#CONFIG_NET_SOCKETS_OBJ_CORE=y

# =========================================================================
# Thread Stack Configuration - nRF54LM20DK measurements
# =========================================================================
# All values measured on nRF54LM20DK using CONFIG_THREAD_ANALYZER.
# Sizing rule: max_hwm / 0.9 (10 % headroom). Override prj.conf values which
# were measured on nRF54LM20DK + nRF7002EB2.
# =========================================================================
# Watermark Bytes 8312/0.9=9235
CONFIG_WIFI_NM_WPA_SUPPLICANT_THREAD_STACK_SIZE=9235
# Watermark Bytes 3600/0.9=4000
CONFIG_WIFI_NM_WPA_SUPPLICANT_WQ_STACK_SIZE=4000
# Watermark Bytes 4560/0.9=5066
CONFIG_SYSTEM_WORKQUEUE_STACK_SIZE=5066
# Watermark Bytes 1512/0.9=1680
CONFIG_NRF70_BH_WQ_STACK_SIZE=4096
# Watermark Bytes 792/0.9=880
CONFIG_NRF70_IRQ_WQ_STACK_SIZE=880

# =========================================================================
# Heap Configuration - nRF54LM20DK measurements
# =========================================================================
# Heap: max_hwm / 0.8 (20 % headroom).
# Watermark Bytes 88248/0.8=110310
CONFIG_HEAP_MEM_POOL_SIZE=110310
```

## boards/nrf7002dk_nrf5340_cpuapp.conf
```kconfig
#
# Copyright (c) 2026 Nordic Semiconductor ASA
#
# SPDX-License-Identifier: LicenseRef-Nordic-5-Clause
#

# =========================================================================
# Configuration coverage priority:
# Command line > Overlay files > project boards/<board>.conf > prj.conf > Board defconfig
# (highest)                                                              (lowest)
# =========================================================================

# =========================================================================
# This file contains only:
#   - System-level configuration that belongs to no single module
#   - Module enable/disable flags
#   - Log-level choices (cannot be set via Kconfig.defaults)
#   - Project-specific overrides that differ from module defaults
#   - Shared cross-module settings (TLS, mbedTLS)
#   - Hardware-specific memory and stack tuning
# Module-specific defaults live in each module's Kconfig.defaults file.
# =========================================================================

# =========================================================================
# prj.conf should contain the following sections, if needed, in this order,
# with the given headings. Config values that already match the Kconfig
# default (or are already selected transitively) should be commented out.
# Top-level section headings use "=" bars; sub-sections within a section
# use "-" bars:
# =========================================================================
# Document versions — keep in sync with docs/pm-prd/PRD.md and docs/dev-specs/overview.md Changelog timestamps
# General System Configuration - General system configuration
# ZEGO Module: button/led/wifi/network - configurations for different Zego modules
# APP  Module: app/ntp/app_http/app_mqtt - configurations for different APP modules
# Thread Stack Configuration - Thread stack configuration
# Heap Configuration - Heap configuration   
# mbedTLS - mbedTLS configuration
# Shell - shell configuration
# Logging Configuration
# Optimization - Optimization configuration
# =========================================================================
# Reminder: this header block (down to this line) should be copied verbatim
# into any new prj.conf-style config file (e.g. new boards/*.conf files) so
# the same section order and bar conventions are followed consistently.
# =========================================================================

# =========================================================================
# ZEGO Module: button/led/wifi_prov - configurations for different Zego modules
# =========================================================================

# -------------------------------------------------------------------------
# button / led — nRF7002DK: 2 user buttons (SW0 = Button 1, SW1 = Button 2), 2 LEDs
# -------------------------------------------------------------------------
CONFIG_ZEGO_BUTTON_NUM_BUTTONS=2
# CONFIG_ZEGO_BUTTON_BACKEND_DK already the brick's default choice.
# CONFIG_ZEGO_BUTTON_BACKEND_DK=y
CONFIG_ZEGO_LED_NUM_LEDS=2
# CONFIG_ZEGO_LED_BACKEND_DK already the brick's default choice.
# CONFIG_ZEGO_LED_BACKEND_DK=y

# -------------------------------------------------------------------------
# wifi_prov — BLE provisioning support
# -------------------------------------------------------------------------
# BLE provisioning does not fit on nRF7002DK (nRF5340, 1 MB flash) when
# a heavy application is also present.  Enable it only if you have enough
# flash headroom; otherwise leave it disabled here and rely on the
# wifi connect / wifi cred shell options for STA provisioning.
# Remove or override this line to re-enable on nRF7002DK.
CONFIG_ZEGO_WIFI_BLE_PROV=n

# =========================================================================
# Thread Stack Configuration - nRF7002DK measurements
# =========================================================================
# All values measured on nRF7002DK using CONFIG_THREAD_ANALYZER.
# Sizing rule: max_hwm / 0.9 (10 % headroom). Override prj.conf values which
# were measured on nRF54LM20DK + nRF7002EB2.
# =========================================================================
# Watermark Bytes 7880/0.9=8755
CONFIG_WIFI_NM_WPA_SUPPLICANT_THREAD_STACK_SIZE=8755
# Watermark Bytes 3552/0.9=3946
CONFIG_WIFI_NM_WPA_SUPPLICANT_WQ_STACK_SIZE=3946
# Watermark Bytes 4560/0.9=5066
CONFIG_SYSTEM_WORKQUEUE_STACK_SIZE=5066
# Watermark Bytes 1168/0.9=1297
CONFIG_NRF70_BH_WQ_STACK_SIZE=1297
# Watermark Bytes 792/0.9=880
CONFIG_NRF70_IRQ_WQ_STACK_SIZE=880

# =========================================================================
# Heap Configuration - nRF7002DK measurements
# =========================================================================
# Heap: max_hwm / 0.8 (20 % headroom).
# Watermark Bytes 88128/0.8=110160
CONFIG_HEAP_MEM_POOL_SIZE=110160

# =========================================================================
# mbedTLS - Silence the "MBEDTLS_PSA_CRYPTO_EXTERNAL_RNG_ALLOW_NON_CSPRNG" build warning
# =========================================================================
# Silence the v3.3.0 Kconfig warning:
#   "MBEDTLS_PSA_CRYPTO_EXTERNAL_RNG_ALLOW_NON_CSPRNG was assigned the value
#    'y' but got the value 'n'"
# The nrf7002dk_nrf5340_cpuapp_defconfig sets this symbol to 'y'.
# NRF_SECURITY selects DISABLE_MBEDTLS_BUILTIN and sets
# MBEDTLS_CFG_FILE="nrf-config.h", making the Kconfig.mbedtls menu
# (depends on MBEDTLS_BUILTIN && MBEDTLS_CFG_FILE="config-mbedtls.h")
# invisible.  The dependency is therefore unmet.  Explicitly clearing the
# symbol here overrides the defconfig assignment so the assigned value ('n')
# matches the evaluated value ('n').
#
# A related warning ("The choice symbol MBEDTLS_PSA_CRYPTO_EXTERNAL_RNG was
# selected (set =y) but no symbol ended up as the choice selection") also
# originates from the board defconfig and cannot be silenced at the app
# level: kconfiglib does not honour "# CONFIG_CHOICE_SYMBOL is not set" for
# choice symbols, so the defconfig's choice assignment persists.  This is a
# known upstream issue (NRF_SECURITY overrides the choice via CMake, but the
# Kconfig layer is left inconsistent).  The warning is harmless; nrf_security
# always provides its own RNG implementation regardless of this choice.
# =========================================================================
# CONFIG_MBEDTLS_PSA_CRYPTO_EXTERNAL_RNG_ALLOW_NON_CSPRNG is not set
```

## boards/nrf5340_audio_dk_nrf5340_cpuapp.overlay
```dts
/*
 * Copyright (c) 2026 Nordic Semiconductor ASA
 *
 * SPDX-License-Identifier: LicenseRef-Nordic-5-Clause
 */

/*
 * nRF5340 Audio DK + nRF7002EK board overlay.
 *
 * The nRF7002EK shield uses UART1 pins for bucken and iovdd-ctrl.  The
 * gpio_fwd node would forward those pins to the network core, which
 * conflicts with the shield's usage.  Disable the entire node so the
 * application core controls the lines directly.
 */
&gpio_fwd {
	status = "disabled";
};

/*
 * Pull down the SPI4 (arduino_spi) lines when idle.  Without this the
 * floating inputs on the nRF7002EK can cause spurious SPI transactions
 * when the interface is not in use.  Mirrors the identical fix applied
 * to nRF5340DK in the upstream nrf7002ek shield overlay.
 */
&pinctrl {
	spi4_default: spi4_default {
		group1 {
			bias-pull-down;
		};
	};

	spi4_sleep: spi4_sleep {
		group1 {
			bias-pull-down;
			low-power-enable;
		};
	};
};
```

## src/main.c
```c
/*
 * Copyright (c) 2026 Nordic Semiconductor ASA
 * SPDX-License-Identifier: LicenseRef-Nordic-5-Clause
 */

#include <ux.h>

int main(void)
{
	zego_ux_print_banner();
	k_sleep(K_FOREVER);
	return 0;
}
```
